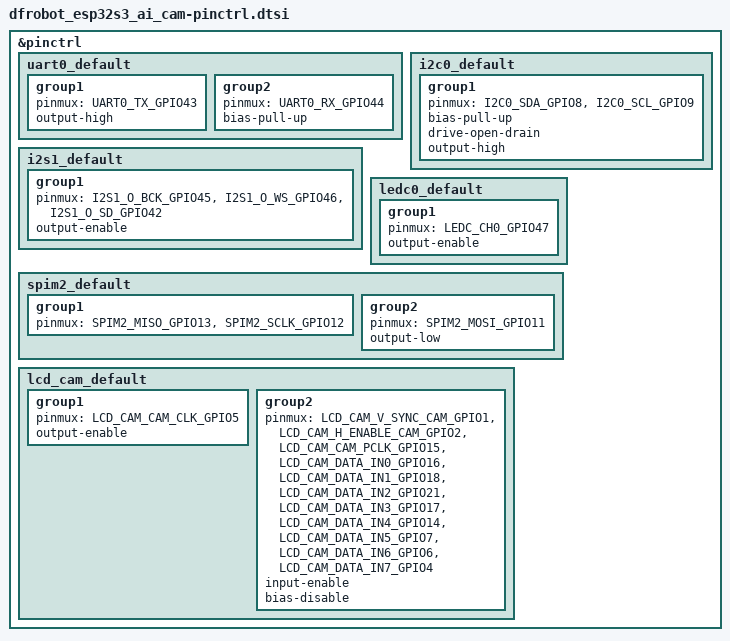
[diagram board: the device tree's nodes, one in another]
/*
 * Copyright (c) 2026 Richard Osterloh <richard.osterloh@gmail.com>
 * SPDX-License-Identifier: Apache-2.0
 */

#include <zephyr/dt-bindings/pinctrl/esp32s3-pinctrl.h>

&pinctrl {
	/* Gravity header */
	uart0_default: uart0_default {
		group1 {
			pinmux = <UART0_TX_GPIO43>;
			output-high;
		};

		group2 {
			pinmux = <UART0_RX_GPIO44>;
			bias-pull-up;
		};
	};

	/* OV3660 SCCB, LTR-308 */
	i2c0_default: i2c0_default {
		group1 {
			pinmux = <I2C0_SDA_GPIO8>,
				 <I2C0_SCL_GPIO9>;
			bias-pull-up;
			drive-open-drain;
			output-high;
		};
	};

	/* MAX98357 amplifier: BCLK, LRCLK, DIN */
	i2s1_default: i2s1_default {
		group1 {
			pinmux = <I2S1_O_BCK_GPIO45>,
				 <I2S1_O_WS_GPIO46>,
				 <I2S1_O_SD_GPIO42>;
			output-enable;
		};
	};

	/* IR illumination LEDs */
	ledc0_default: ledc0_default {
		group1 {
			pinmux = <LEDC_CH0_GPIO47>;
			output-enable;
		};
	};

	/* microSD over SPI; CS (GPIO10) is a GPIO */
	spim2_default: spim2_default {
		group1 {
			pinmux = <SPIM2_MISO_GPIO13>,
				 <SPIM2_SCLK_GPIO12>;
		};

		group2 {
			pinmux = <SPIM2_MOSI_GPIO11>;
			output-low;
		};
	};

	/* OV3660 8-bit DVP: Y2..Y9 = D0..D7 */
	lcd_cam_default: lcd_cam_default {
		group1 {
			pinmux = <LCD_CAM_CAM_CLK_GPIO5>;
			output-enable;
		};

		group2 {
			pinmux = <LCD_CAM_V_SYNC_CAM_GPIO1>,
				 <LCD_CAM_H_ENABLE_CAM_GPIO2>,
				 <LCD_CAM_CAM_PCLK_GPIO15>,
				 <LCD_CAM_DATA_IN0_GPIO16>,
				 <LCD_CAM_DATA_IN1_GPIO18>,
				 <LCD_CAM_DATA_IN2_GPIO21>,
				 <LCD_CAM_DATA_IN3_GPIO17>,
				 <LCD_CAM_DATA_IN4_GPIO14>,
				 <LCD_CAM_DATA_IN5_GPIO7>,
				 <LCD_CAM_DATA_IN6_GPIO6>,
				 <LCD_CAM_DATA_IN7_GPIO4>;
			input-enable;
			bias-disable;
		};
	};
};
